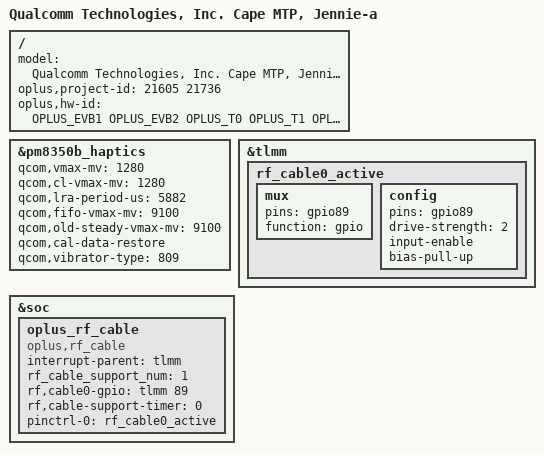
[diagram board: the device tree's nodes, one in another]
/dts-v1/;
/plugin/;
#include <dt-bindings/oplus/hw-id.h>
#include "../qcom/cape-mtp-pm8010-overlay.dts"
#include "cape_overlay_common.dtsi"
#include "jennie_21605_overlay_common.dtsi"
#include "nfc/jennie-nfc-sn100t.dtsi"
#include "tp/oplus_tp_overlay_common.dtsi"
#include "oplus_uff/oplus_uff_sm8475.dtsi"
#include "sensor/jennie-oplus-sensor.dtsi"
#include "shouder/jennie_shouder_chipsea_f71.dtsi"
#include "oplus_chg/oplus-chg-21605.dtsi"

/ {
	model = "Qualcomm Technologies, Inc. Cape MTP, Jennie-a";
        oplus,project-id = <21605 21736>;
        oplus,hw-id = <OPLUS_EVB1 OPLUS_EVB2 OPLUS_T0 OPLUS_T1 OPLUS_EVT1 OPLUS_EVT2 OPLUS_EVT3 OPLUS_DVT1 OPLUS_DVT2 OPLUS_DVT3 OPLUS_PVT1 OPLUS_PVT2 OPLUS_MP1 OPLUS_MP2 OPLUS_MP3>;
};

&pm8350b_haptics {
    qcom,vmax-mv = <1280>;
    qcom,cl-vmax-mv = <1280>;
    qcom,lra-period-us = <5882>;
    qcom,fifo-vmax-mv = <9100>;
    qcom,old-steady-vmax-mv = <9100>;
    qcom,cal-data-restore;
    qcom,vibrator-type = <809>;//ela0809
};

&tlmm {
  rf_cable0_active: rf_cable0_active {
    mux {
      pins = "gpio89";
      function = "gpio";
    };
    config {
      pins = "gpio89";
      drive-strength = <2>;
      input-enable;
      bias-pull-up;
    };
  };
};

&soc {
  oplus_rf_cable {
    compatible = "oplus,rf_cable";
    interrupt-parent = <&tlmm>;
    rf_cable_support_num = <1>;
    rf,cable0-gpio = <&tlmm 89 0>;
    rf,cable-support-timer = <0>;
    pinctrl-names = "rf_cable_active";
    pinctrl-0 = <&rf_cable0_active>;
  };
};
